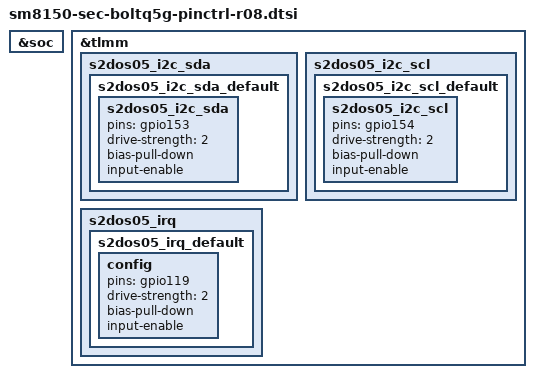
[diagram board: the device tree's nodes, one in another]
/* Copyright (c) 2016-2017, The Linux Foundation. All rights reserved.
 *
 * This program is free software; you can redistribute it and/or modify
 * it under the terms of the GNU General Public License version 2 and
 * only version 2 as published by the Free Software Foundation.
 *
 * This program is distributed in the hope that it will be useful,
 * but WITHOUT ANY WARRANTY; without even the implied warranty of
 * MERCHANTABILITY or FITNESS FOR A PARTICULAR PURPOSE.  See the
 * GNU General Public License for more details.
 */

#include "sm8150-sec-boltq5g-pinctrl-common.dtsi"

&soc {
	/* tlmm: pinctrl@03400000 { }; */
};

&tlmm {
	s2dos05_i2c_sda {
		s2dos05_i2c_sda_default: s2dos05_i2c_sda_default {
			s2dos05_i2c_sda {
				pins = "gpio153";
				drive-strength = <2>;
				bias-pull-down;
				input-enable;
			};
		};
	};
	s2dos05_i2c_scl {
		s2dos05_i2c_scl_default: s2dos05_i2c_scl_default {
			s2dos05_i2c_scl {
				pins = "gpio154";
				drive-strength = <2>;
				bias-pull-down;
				input-enable;
			};
		};
	};
	s2dos05_irq {
		s2dos05_irq_default: s2dos05_irq_default {
			config {
				pins = "gpio119";
				drive-strength = <2>;
				bias-pull-down;
				input-enable;
			};
		};
	};
};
